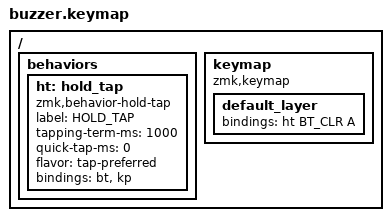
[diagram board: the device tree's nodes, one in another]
#include <behaviors.dtsi>
#include <dt-bindings/zmk/keys.h>
#include <dt-bindings/zmk/bt.h>

/ {
    behaviors {
        /* Define the Hold-Tap behavior */
        ht: hold_tap {
            compatible = "zmk,behavior-hold-tap";
            label = "HOLD_TAP";
            #binding-cells = <2>;
            tapping-term-ms = <1000>; /* Hold for 1000 milliseconds (1 second) */
            quick-tap-ms = <0>;
            flavor = "tap-preferred";
            bindings = <&bt>, <&kp>;
        };
    };

    keymap {
        compatible = "zmk,keymap";

        default_layer {
            /* If held, clear BT profile. If tapped, press 'A' */
            bindings = <
                &ht BT_CLR A
            >;
        };
    };
};
